# ESP32-H21 register map
Vendor: ESPRESSIF SYSTEMS (SHANGHAI) CO., LTD.; Series: ESP32 H-Series; File version: 1
CPU: RV32IMAC r0p0, little endian, no MPU, no FPU, 0 interrupt priority bits
Address unit: 32 bits
Registers are 32-bit, read-write, reset 0x0 unless marked. A register's access mark holds for its fields unless they carry their own. Offsets are from the block's base; [hi:lo] are bit positions; {n}, {i} and the like mark numbered series.

## SPI0 (part 2 of 2) — SPI (Serial Peripheral Interface) Controller 0
Base 0x60002000
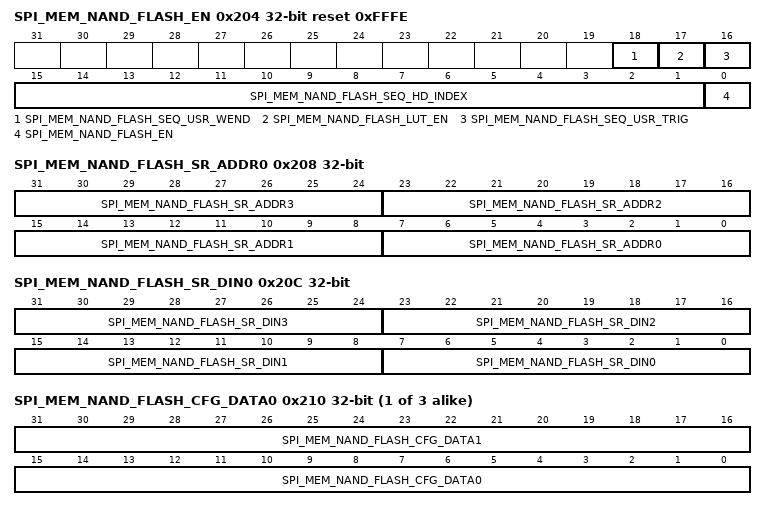
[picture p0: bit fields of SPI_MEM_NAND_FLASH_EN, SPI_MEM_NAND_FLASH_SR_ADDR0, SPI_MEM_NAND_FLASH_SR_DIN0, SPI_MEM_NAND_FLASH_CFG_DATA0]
0x204 SPI_MEM_NAND_FLASH_EN ro reset 0xFFFE — NAND FLASH control register
  [18] SPI_MEM_NAND_FLASH_SEQ_USR_WEND — Used with SPI_MEM_NAND_FLASH_SEQ_USR_TRIG to indecate the last page program ,and to excute page excute. 1: write end 0: write in a page size.
  [17] SPI_MEM_NAND_FLASH_LUT_EN — NAND FLASH spi seq & cmd lut cfg en. 1: enable 0: disable.
  [16] SPI_MEM_NAND_FLASH_SEQ_USR_TRIG — NAND FLASH spi seq user trigger configure register. SPI_MEM_NAND_FLASH_SEQ_USR_TRIG is corresponds to SPI_MEM_NAND_FLASH_SEQ_HD_INDEX[14:10].1: enable 0: disable.
  [15:1] SPI_MEM_NAND_FLASH_SEQ_HD_INDEX — NAND FLASH spi seq head index configure register. Every 5 bits represent the 1st index of a SPI CMD sequence.[14:10]:usr; [9:5]:axi_rd; [4:0]:axi_wr.
  [0] SPI_MEM_NAND_FLASH_EN — NAND FLASH function enable signal. 1: Enable NAND FLASH, Disable NOR FLASH. 0: Disable NAND FLASH, Enable NOR FLASH.
0x208 SPI_MEM_NAND_FLASH_SR_ADDR0 ro — NAND FLASH SPI SEQ control register
  [8n+7:8n] SPI_MEM_NAND_FLASH_SR_ADDR{n} (n=0..3) — configure state register address for SPI SEQ need. If OIP is in address C0H , user could configure C0H into this register
0x20C SPI_MEM_NAND_FLASH_SR_DIN0 ro — NAND FLASH SPI SEQ control register
  [8n+7:8n] SPI_MEM_NAND_FLASH_SR_DIN{n} (n=0..3) — spi read state register data to this register for SPI SEQ need. SPI_MEM_NAND_FLASH_SR_DIN0_REG corresponds to SPI_MEM_NAND_FLASH_SR_ADDR0_REG.
{0x210+4i} SPI_MEM_NAND_FLASH_CFG_DATA{i} ro (i=0..2) — NAND FLASH SPI SEQ control register
  [31:16] SPI_MEM_NAND_FLASH_CFG_DATA{2i+1} — configure data for SPI SEQ din/dout need. The data could be use to configure NAND FLASH or compare read data
  [15:0] SPI_MEM_NAND_FLASH_CFG_DATA{2i} — configure data for SPI SEQ din/dout need. The data could be use to configure NAND FLASH or compare read data
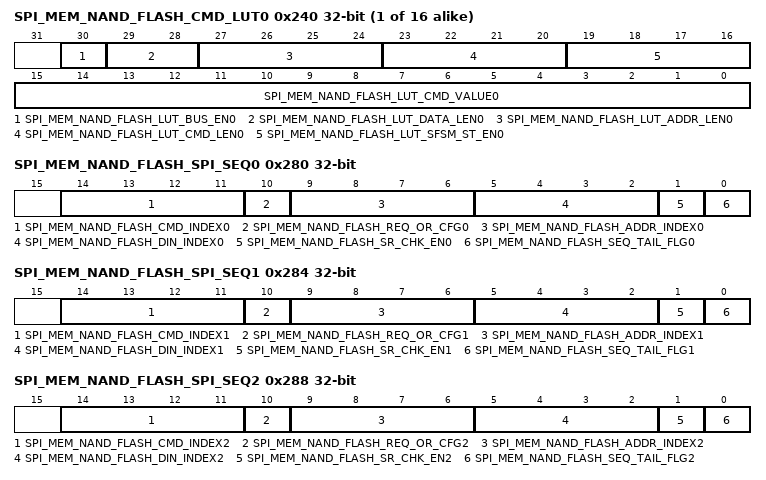
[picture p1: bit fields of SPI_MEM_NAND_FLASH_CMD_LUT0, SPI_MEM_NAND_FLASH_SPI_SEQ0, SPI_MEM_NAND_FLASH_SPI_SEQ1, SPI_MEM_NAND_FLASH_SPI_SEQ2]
{0x240+4i} SPI_MEM_NAND_FLASH_CMD_LUT{i} ro (i=0..15) — MSPI NAND FLASH CMD LUT control register
  [30] SPI_MEM_NAND_FLASH_LUT_BUS_EN{i} — MSPI NAND FLASH config spi_bus_en at cmd lut address {i},SPI could use DUAL/QUAD mode while enable, SPI could use SINGLE mode while disable.1:Enable. 0:Disable.(Note these registers are described to indicate the SPI_MEM_NAND_FLASH_CMD_LUT{i}_REG's field. The number of CMD LUT entries can be defined by the user, but cannot exceed 16 )
  [29:28] SPI_MEM_NAND_FLASH_LUT_DATA_LEN{i} — MSPI NAND FLASH config data length at cmd lut address {i}.
  [27:24] SPI_MEM_NAND_FLASH_LUT_ADDR_LEN{i} — MSPI NAND FLASH config address length at cmd lut address {i}.
  [23:20] SPI_MEM_NAND_FLASH_LUT_CMD_LEN{i} — MSPI NAND FLASH config cmd length at cmd lut address {i}.
  [19:16] SPI_MEM_NAND_FLASH_LUT_SFSM_ST_EN{i} — MSPI NAND FLASH config sfsm_st_en at cmd lut address {i}.[3]-ADDR period enable; [2]-DUMMY period enable; [1]-DIN period; [0]-DOUT period.
  [15:0] SPI_MEM_NAND_FLASH_LUT_CMD_VALUE{i} — MSPI NAND FLASH config cmd value at cmd lut address {i}.
0x280 SPI_MEM_NAND_FLASH_SPI_SEQ0 ro — NAND FLASH SPI SEQ control register
  [14:11] SPI_MEM_NAND_FLASH_CMD_INDEX0 — MSPI NAND FLASH config spi_cmd_index at spi seq index 0. Use to find SPI command in CMD LUT.(Note these registers are described to indicate the SPI_MEM_NAND_FLASH_SPI_SEQ_REG' fieldd The number of CMD LUT entries can be defined by the user, but cannot exceed 16 )
  [10] SPI_MEM_NAND_FLASH_REQ_OR_CFG0 — MSPI NAND FLASH config reg_or_cfg at spi seq index 0. 1: AXI/APB request 0: SPI SEQ configuration.
  [9:6] SPI_MEM_NAND_FLASH_ADDR_INDEX0 — MSPI NAND FLASH config addr_index at spi seq index 0. Use with SPI_MEM_NAND_FLASH_SR_ADDR
  [5:2] SPI_MEM_NAND_FLASH_DIN_INDEX0 — MSPI NAND FLASH config din_index at spi seq index 0. Use with SPI_MEM_NAND_FLASH_CFG_DATA
  [1] SPI_MEM_NAND_FLASH_SR_CHK_EN0 — MSPI NAND FLASH config sr_chk_en at spi seq index 0. 1: enable 0: disable.
  [0] SPI_MEM_NAND_FLASH_SEQ_TAIL_FLG0 — MSPI NAND FLASH config seq_tail_flg at spi seq index 0.1: The last index for sequence. 0: Not the last index.
0x284 SPI_MEM_NAND_FLASH_SPI_SEQ1 ro — NAND FLASH SPI SEQ control register
  [14:11] SPI_MEM_NAND_FLASH_CMD_INDEX1 — MSPI NAND FLASH config spi_cmd_index at spi seq index 1. Use to find SPI command in CMD LUT.(Note these registers are described to indicate the SPI_MEM_NAND_FLASH_SPI_SEQ_REG' fieldd The number of CMD LUT entries can be defined by the user, but cannot exceed 16 )
  [10] SPI_MEM_NAND_FLASH_REQ_OR_CFG1 — MSPI NAND FLASH config reg_or_cfg at spi seq index 1. 1: AXI/APB request 0: SPI SEQ configuration.
  [9:6] SPI_MEM_NAND_FLASH_ADDR_INDEX1 — MSPI NAND FLASH config addr_index at spi seq index 1. Use with SPI_MEM_NAND_FLASH_SR_ADDR
  [5:2] SPI_MEM_NAND_FLASH_DIN_INDEX1 — MSPI NAND FLASH config din_index at spi seq index 1. Use with SPI_MEM_NAND_FLASH_CFG_DATA
  [1] SPI_MEM_NAND_FLASH_SR_CHK_EN1 — MSPI NAND FLASH config sr_chk_en at spi seq index 1. 1: enable 0: disable.
  [0] SPI_MEM_NAND_FLASH_SEQ_TAIL_FLG1 — MSPI NAND FLASH config seq_tail_flg at spi seq index 1.1: The last index for sequence. 0: Not the last index.
0x288 SPI_MEM_NAND_FLASH_SPI_SEQ2 ro — NAND FLASH SPI SEQ control register
  [14:11] SPI_MEM_NAND_FLASH_CMD_INDEX2 — MSPI NAND FLASH config spi_cmd_index at spi seq index 2. Use to find SPI command in CMD LUT.(Note these registers are described to indicate the SPI_MEM_NAND_FLASH_SPI_SEQ_REG' fieldd The number of CMD LUT entries can be defined by the user, but cannot exceed 16 )
  [10] SPI_MEM_NAND_FLASH_REQ_OR_CFG2 — MSPI NAND FLASH config reg_or_cfg at spi seq index 2. 1: AXI/APB request 0: SPI SEQ configuration.
  [9:6] SPI_MEM_NAND_FLASH_ADDR_INDEX2 — MSPI NAND FLASH config addr_index at spi seq index 2. Use with SPI_MEM_NAND_FLASH_SR_ADDR
  [5:2] SPI_MEM_NAND_FLASH_DIN_INDEX2 — MSPI NAND FLASH config din_index at spi seq index 2. Use with SPI_MEM_NAND_FLASH_CFG_DATA
  [1] SPI_MEM_NAND_FLASH_SR_CHK_EN2 — MSPI NAND FLASH config sr_chk_en at spi seq index 2. 1: enable 0: disable.
  [0] SPI_MEM_NAND_FLASH_SEQ_TAIL_FLG2 — MSPI NAND FLASH config seq_tail_flg at spi seq index 2.1: The last index for sequence. 0: Not the last index.
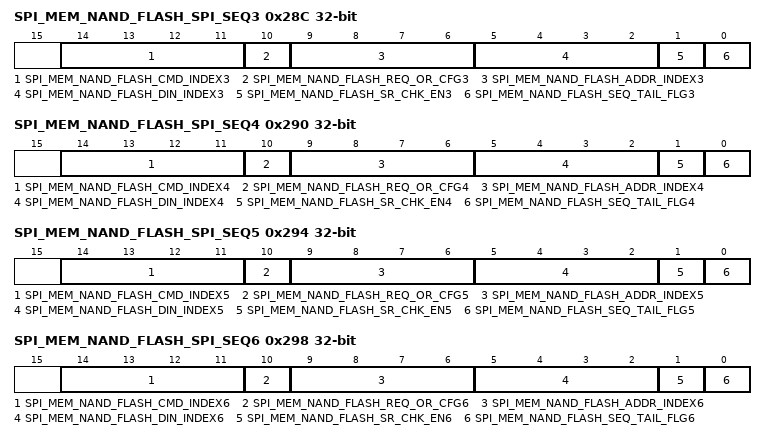
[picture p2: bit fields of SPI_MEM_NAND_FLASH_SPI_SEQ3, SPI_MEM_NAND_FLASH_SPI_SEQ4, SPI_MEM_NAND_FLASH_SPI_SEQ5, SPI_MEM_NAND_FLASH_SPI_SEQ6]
0x28C SPI_MEM_NAND_FLASH_SPI_SEQ3 ro — NAND FLASH SPI SEQ control register
  [14:11] SPI_MEM_NAND_FLASH_CMD_INDEX3 — MSPI NAND FLASH config spi_cmd_index at spi seq index 3. Use to find SPI command in CMD LUT.(Note these registers are described to indicate the SPI_MEM_NAND_FLASH_SPI_SEQ_REG' fieldd The number of CMD LUT entries can be defined by the user, but cannot exceed 16 )
  [10] SPI_MEM_NAND_FLASH_REQ_OR_CFG3 — MSPI NAND FLASH config reg_or_cfg at spi seq index 3. 1: AXI/APB request 0: SPI SEQ configuration.
  [9:6] SPI_MEM_NAND_FLASH_ADDR_INDEX3 — MSPI NAND FLASH config addr_index at spi seq index 3. Use with SPI_MEM_NAND_FLASH_SR_ADDR
  [5:2] SPI_MEM_NAND_FLASH_DIN_INDEX3 — MSPI NAND FLASH config din_index at spi seq index 3. Use with SPI_MEM_NAND_FLASH_CFG_DATA
  [1] SPI_MEM_NAND_FLASH_SR_CHK_EN3 — MSPI NAND FLASH config sr_chk_en at spi seq index 3. 1: enable 0: disable.
  [0] SPI_MEM_NAND_FLASH_SEQ_TAIL_FLG3 — MSPI NAND FLASH config seq_tail_flg at spi seq index 3.1: The last index for sequence. 0: Not the last index.
0x290 SPI_MEM_NAND_FLASH_SPI_SEQ4 ro — NAND FLASH SPI SEQ control register
  [14:11] SPI_MEM_NAND_FLASH_CMD_INDEX4 — MSPI NAND FLASH config spi_cmd_index at spi seq index 4. Use to find SPI command in CMD LUT.(Note these registers are described to indicate the SPI_MEM_NAND_FLASH_SPI_SEQ_REG' fieldd The number of CMD LUT entries can be defined by the user, but cannot exceed 16 )
  [10] SPI_MEM_NAND_FLASH_REQ_OR_CFG4 — MSPI NAND FLASH config reg_or_cfg at spi seq index 4. 1: AXI/APB request 0: SPI SEQ configuration.
  [9:6] SPI_MEM_NAND_FLASH_ADDR_INDEX4 — MSPI NAND FLASH config addr_index at spi seq index 4. Use with SPI_MEM_NAND_FLASH_SR_ADDR
  [5:2] SPI_MEM_NAND_FLASH_DIN_INDEX4 — MSPI NAND FLASH config din_index at spi seq index 4. Use with SPI_MEM_NAND_FLASH_CFG_DATA
  [1] SPI_MEM_NAND_FLASH_SR_CHK_EN4 — MSPI NAND FLASH config sr_chk_en at spi seq index 4. 1: enable 0: disable.
  [0] SPI_MEM_NAND_FLASH_SEQ_TAIL_FLG4 — MSPI NAND FLASH config seq_tail_flg at spi seq index 4.1: The last index for sequence. 0: Not the last index.
0x294 SPI_MEM_NAND_FLASH_SPI_SEQ5 ro — NAND FLASH SPI SEQ control register
  [14:11] SPI_MEM_NAND_FLASH_CMD_INDEX5 — MSPI NAND FLASH config spi_cmd_index at spi seq index 5. Use to find SPI command in CMD LUT.(Note these registers are described to indicate the SPI_MEM_NAND_FLASH_SPI_SEQ_REG' fieldd The number of CMD LUT entries can be defined by the user, but cannot exceed 16 )
  [10] SPI_MEM_NAND_FLASH_REQ_OR_CFG5 — MSPI NAND FLASH config reg_or_cfg at spi seq index 5. 1: AXI/APB request 0: SPI SEQ configuration.
  [9:6] SPI_MEM_NAND_FLASH_ADDR_INDEX5 — MSPI NAND FLASH config addr_index at spi seq index 5. Use with SPI_MEM_NAND_FLASH_SR_ADDR
  [5:2] SPI_MEM_NAND_FLASH_DIN_INDEX5 — MSPI NAND FLASH config din_index at spi seq index 5. Use with SPI_MEM_NAND_FLASH_CFG_DATA
  [1] SPI_MEM_NAND_FLASH_SR_CHK_EN5 — MSPI NAND FLASH config sr_chk_en at spi seq index 5. 1: enable 0: disable.
  [0] SPI_MEM_NAND_FLASH_SEQ_TAIL_FLG5 — MSPI NAND FLASH config seq_tail_flg at spi seq index 5.1: The last index for sequence. 0: Not the last index.
0x298 SPI_MEM_NAND_FLASH_SPI_SEQ6 ro — NAND FLASH SPI SEQ control register
  [14:11] SPI_MEM_NAND_FLASH_CMD_INDEX6 — MSPI NAND FLASH config spi_cmd_index at spi seq index 6. Use to find SPI command in CMD LUT.(Note these registers are described to indicate the SPI_MEM_NAND_FLASH_SPI_SEQ_REG' fieldd The number of CMD LUT entries can be defined by the user, but cannot exceed 16 )
  [10] SPI_MEM_NAND_FLASH_REQ_OR_CFG6 — MSPI NAND FLASH config reg_or_cfg at spi seq index 6. 1: AXI/APB request 0: SPI SEQ configuration.
  [9:6] SPI_MEM_NAND_FLASH_ADDR_INDEX6 — MSPI NAND FLASH config addr_index at spi seq index 6. Use with SPI_MEM_NAND_FLASH_SR_ADDR
  [5:2] SPI_MEM_NAND_FLASH_DIN_INDEX6 — MSPI NAND FLASH config din_index at spi seq index 6. Use with SPI_MEM_NAND_FLASH_CFG_DATA
  [1] SPI_MEM_NAND_FLASH_SR_CHK_EN6 — MSPI NAND FLASH config sr_chk_en at spi seq index 6. 1: enable 0: disable.
  [0] SPI_MEM_NAND_FLASH_SEQ_TAIL_FLG6 — MSPI NAND FLASH config seq_tail_flg at spi seq index 6.1: The last index for sequence. 0: Not the last index.
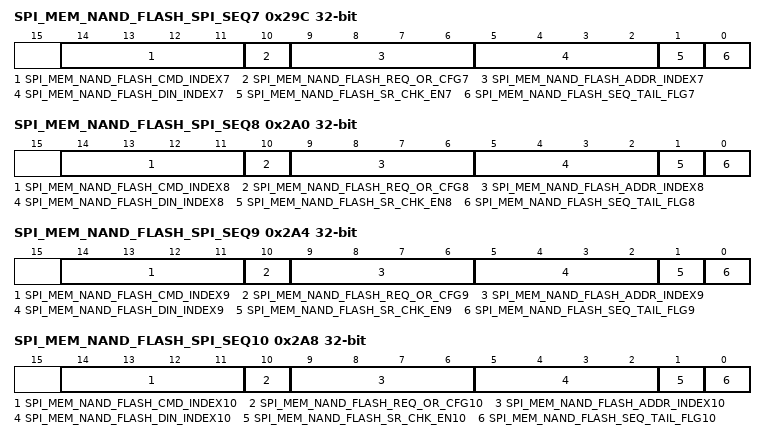
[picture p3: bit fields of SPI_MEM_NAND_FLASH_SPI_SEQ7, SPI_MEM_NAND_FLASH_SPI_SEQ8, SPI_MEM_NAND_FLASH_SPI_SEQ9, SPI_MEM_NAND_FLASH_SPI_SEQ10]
0x29C SPI_MEM_NAND_FLASH_SPI_SEQ7 ro — NAND FLASH SPI SEQ control register
  [14:11] SPI_MEM_NAND_FLASH_CMD_INDEX7 — MSPI NAND FLASH config spi_cmd_index at spi seq index 7. Use to find SPI command in CMD LUT.(Note these registers are described to indicate the SPI_MEM_NAND_FLASH_SPI_SEQ_REG' fieldd The number of CMD LUT entries can be defined by the user, but cannot exceed 16 )
  [10] SPI_MEM_NAND_FLASH_REQ_OR_CFG7 — MSPI NAND FLASH config reg_or_cfg at spi seq index 7. 1: AXI/APB request 0: SPI SEQ configuration.
  [9:6] SPI_MEM_NAND_FLASH_ADDR_INDEX7 — MSPI NAND FLASH config addr_index at spi seq index 7. Use with SPI_MEM_NAND_FLASH_SR_ADDR
  [5:2] SPI_MEM_NAND_FLASH_DIN_INDEX7 — MSPI NAND FLASH config din_index at spi seq index 7. Use with SPI_MEM_NAND_FLASH_CFG_DATA
  [1] SPI_MEM_NAND_FLASH_SR_CHK_EN7 — MSPI NAND FLASH config sr_chk_en at spi seq index 7. 1: enable 0: disable.
  [0] SPI_MEM_NAND_FLASH_SEQ_TAIL_FLG7 — MSPI NAND FLASH config seq_tail_flg at spi seq index 7.1: The last index for sequence. 0: Not the last index.
0x2A0 SPI_MEM_NAND_FLASH_SPI_SEQ8 ro — NAND FLASH SPI SEQ control register
  [14:11] SPI_MEM_NAND_FLASH_CMD_INDEX8 — MSPI NAND FLASH config spi_cmd_index at spi seq index 8. Use to find SPI command in CMD LUT.(Note these registers are described to indicate the SPI_MEM_NAND_FLASH_SPI_SEQ_REG' fieldd The number of CMD LUT entries can be defined by the user, but cannot exceed 16 )
  [10] SPI_MEM_NAND_FLASH_REQ_OR_CFG8 — MSPI NAND FLASH config reg_or_cfg at spi seq index 8. 1: AXI/APB request 0: SPI SEQ configuration.
  [9:6] SPI_MEM_NAND_FLASH_ADDR_INDEX8 — MSPI NAND FLASH config addr_index at spi seq index 8. Use with SPI_MEM_NAND_FLASH_SR_ADDR
  [5:2] SPI_MEM_NAND_FLASH_DIN_INDEX8 — MSPI NAND FLASH config din_index at spi seq index 8. Use with SPI_MEM_NAND_FLASH_CFG_DATA
  [1] SPI_MEM_NAND_FLASH_SR_CHK_EN8 — MSPI NAND FLASH config sr_chk_en at spi seq index 8. 1: enable 0: disable.
  [0] SPI_MEM_NAND_FLASH_SEQ_TAIL_FLG8 — MSPI NAND FLASH config seq_tail_flg at spi seq index 8.1: The last index for sequence. 0: Not the last index.
0x2A4 SPI_MEM_NAND_FLASH_SPI_SEQ9 ro — NAND FLASH SPI SEQ control register
  [14:11] SPI_MEM_NAND_FLASH_CMD_INDEX9 — MSPI NAND FLASH config spi_cmd_index at spi seq index 9. Use to find SPI command in CMD LUT.(Note these registers are described to indicate the SPI_MEM_NAND_FLASH_SPI_SEQ_REG' fieldd The number of CMD LUT entries can be defined by the user, but cannot exceed 16 )
  [10] SPI_MEM_NAND_FLASH_REQ_OR_CFG9 — MSPI NAND FLASH config reg_or_cfg at spi seq index 9. 1: AXI/APB request 0: SPI SEQ configuration.
  [9:6] SPI_MEM_NAND_FLASH_ADDR_INDEX9 — MSPI NAND FLASH config addr_index at spi seq index 9. Use with SPI_MEM_NAND_FLASH_SR_ADDR
  [5:2] SPI_MEM_NAND_FLASH_DIN_INDEX9 — MSPI NAND FLASH config din_index at spi seq index 9. Use with SPI_MEM_NAND_FLASH_CFG_DATA
  [1] SPI_MEM_NAND_FLASH_SR_CHK_EN9 — MSPI NAND FLASH config sr_chk_en at spi seq index 9. 1: enable 0: disable.
  [0] SPI_MEM_NAND_FLASH_SEQ_TAIL_FLG9 — MSPI NAND FLASH config seq_tail_flg at spi seq index 9.1: The last index for sequence. 0: Not the last index.
0x2A8 SPI_MEM_NAND_FLASH_SPI_SEQ10 ro — NAND FLASH SPI SEQ control register
  [14:11] SPI_MEM_NAND_FLASH_CMD_INDEX10 — MSPI NAND FLASH config spi_cmd_index at spi seq index 10. Use to find SPI command in CMD LUT.(Note these registers are described to indicate the SPI_MEM_NAND_FLASH_SPI_SEQ_REG' fieldd The number of CMD LUT entries can be defined by the user, but cannot exceed 16 )
  [10] SPI_MEM_NAND_FLASH_REQ_OR_CFG10 — MSPI NAND FLASH config reg_or_cfg at spi seq index 10. 1: AXI/APB request 0: SPI SEQ configuration.
  [9:6] SPI_MEM_NAND_FLASH_ADDR_INDEX10 — MSPI NAND FLASH config addr_index at spi seq index 10. Use with SPI_MEM_NAND_FLASH_SR_ADDR
  [5:2] SPI_MEM_NAND_FLASH_DIN_INDEX10 — MSPI NAND FLASH config din_index at spi seq index 10. Use with SPI_MEM_NAND_FLASH_CFG_DATA
  [1] SPI_MEM_NAND_FLASH_SR_CHK_EN10 — MSPI NAND FLASH config sr_chk_en at spi seq index 10. 1: enable 0: disable.
  [0] SPI_MEM_NAND_FLASH_SEQ_TAIL_FLG10 — MSPI NAND FLASH config seq_tail_flg at spi seq index 10.1: The last index for sequence. 0: Not the last index.
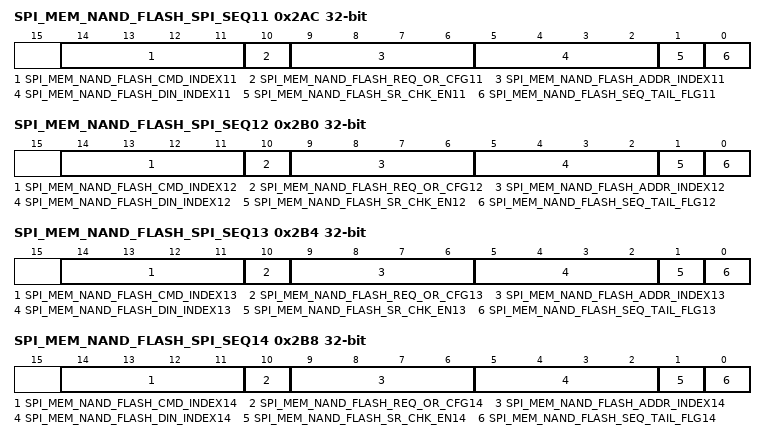
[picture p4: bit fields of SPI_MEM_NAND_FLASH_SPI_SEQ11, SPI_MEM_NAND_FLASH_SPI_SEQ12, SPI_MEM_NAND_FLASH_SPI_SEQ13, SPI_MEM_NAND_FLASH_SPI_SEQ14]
0x2AC SPI_MEM_NAND_FLASH_SPI_SEQ11 ro — NAND FLASH SPI SEQ control register
  [14:11] SPI_MEM_NAND_FLASH_CMD_INDEX11 — MSPI NAND FLASH config spi_cmd_index at spi seq index 11. Use to find SPI command in CMD LUT.(Note these registers are described to indicate the SPI_MEM_NAND_FLASH_SPI_SEQ_REG' fieldd The number of CMD LUT entries can be defined by the user, but cannot exceed 16 )
  [10] SPI_MEM_NAND_FLASH_REQ_OR_CFG11 — MSPI NAND FLASH config reg_or_cfg at spi seq index 11. 1: AXI/APB request 0: SPI SEQ configuration.
  [9:6] SPI_MEM_NAND_FLASH_ADDR_INDEX11 — MSPI NAND FLASH config addr_index at spi seq index 11. Use with SPI_MEM_NAND_FLASH_SR_ADDR
  [5:2] SPI_MEM_NAND_FLASH_DIN_INDEX11 — MSPI NAND FLASH config din_index at spi seq index 11. Use with SPI_MEM_NAND_FLASH_CFG_DATA
  [1] SPI_MEM_NAND_FLASH_SR_CHK_EN11 — MSPI NAND FLASH config sr_chk_en at spi seq index 11. 1: enable 0: disable.
  [0] SPI_MEM_NAND_FLASH_SEQ_TAIL_FLG11 — MSPI NAND FLASH config seq_tail_flg at spi seq index 11.1: The last index for sequence. 0: Not the last index.
0x2B0 SPI_MEM_NAND_FLASH_SPI_SEQ12 ro — NAND FLASH SPI SEQ control register
  [14:11] SPI_MEM_NAND_FLASH_CMD_INDEX12 — MSPI NAND FLASH config spi_cmd_index at spi seq index 12. Use to find SPI command in CMD LUT.(Note these registers are described to indicate the SPI_MEM_NAND_FLASH_SPI_SEQ_REG' fieldd The number of CMD LUT entries can be defined by the user, but cannot exceed 16 )
  [10] SPI_MEM_NAND_FLASH_REQ_OR_CFG12 — MSPI NAND FLASH config reg_or_cfg at spi seq index 12. 1: AXI/APB request 0: SPI SEQ configuration.
  [9:6] SPI_MEM_NAND_FLASH_ADDR_INDEX12 — MSPI NAND FLASH config addr_index at spi seq index 12. Use with SPI_MEM_NAND_FLASH_SR_ADDR
  [5:2] SPI_MEM_NAND_FLASH_DIN_INDEX12 — MSPI NAND FLASH config din_index at spi seq index 12. Use with SPI_MEM_NAND_FLASH_CFG_DATA
  [1] SPI_MEM_NAND_FLASH_SR_CHK_EN12 — MSPI NAND FLASH config sr_chk_en at spi seq index 12. 1: enable 0: disable.
  [0] SPI_MEM_NAND_FLASH_SEQ_TAIL_FLG12 — MSPI NAND FLASH config seq_tail_flg at spi seq index 12.1: The last index for sequence. 0: Not the last index.
0x2B4 SPI_MEM_NAND_FLASH_SPI_SEQ13 ro — NAND FLASH SPI SEQ control register
  [14:11] SPI_MEM_NAND_FLASH_CMD_INDEX13 — MSPI NAND FLASH config spi_cmd_index at spi seq index 13. Use to find SPI command in CMD LUT.(Note these registers are described to indicate the SPI_MEM_NAND_FLASH_SPI_SEQ_REG' fieldd The number of CMD LUT entries can be defined by the user, but cannot exceed 16 )
  [10] SPI_MEM_NAND_FLASH_REQ_OR_CFG13 — MSPI NAND FLASH config reg_or_cfg at spi seq index 13. 1: AXI/APB request 0: SPI SEQ configuration.
  [9:6] SPI_MEM_NAND_FLASH_ADDR_INDEX13 — MSPI NAND FLASH config addr_index at spi seq index 13. Use with SPI_MEM_NAND_FLASH_SR_ADDR
  [5:2] SPI_MEM_NAND_FLASH_DIN_INDEX13 — MSPI NAND FLASH config din_index at spi seq index 13. Use with SPI_MEM_NAND_FLASH_CFG_DATA
  [1] SPI_MEM_NAND_FLASH_SR_CHK_EN13 — MSPI NAND FLASH config sr_chk_en at spi seq index 13. 1: enable 0: disable.
  [0] SPI_MEM_NAND_FLASH_SEQ_TAIL_FLG13 — MSPI NAND FLASH config seq_tail_flg at spi seq index 13.1: The last index for sequence. 0: Not the last index.
0x2B8 SPI_MEM_NAND_FLASH_SPI_SEQ14 ro — NAND FLASH SPI SEQ control register
  [14:11] SPI_MEM_NAND_FLASH_CMD_INDEX14 — MSPI NAND FLASH config spi_cmd_index at spi seq index 14. Use to find SPI command in CMD LUT.(Note these registers are described to indicate the SPI_MEM_NAND_FLASH_SPI_SEQ_REG' fieldd The number of CMD LUT entries can be defined by the user, but cannot exceed 16 )
  [10] SPI_MEM_NAND_FLASH_REQ_OR_CFG14 — MSPI NAND FLASH config reg_or_cfg at spi seq index 14. 1: AXI/APB request 0: SPI SEQ configuration.
  [9:6] SPI_MEM_NAND_FLASH_ADDR_INDEX14 — MSPI NAND FLASH config addr_index at spi seq index 14. Use with SPI_MEM_NAND_FLASH_SR_ADDR
  [5:2] SPI_MEM_NAND_FLASH_DIN_INDEX14 — MSPI NAND FLASH config din_index at spi seq index 14. Use with SPI_MEM_NAND_FLASH_CFG_DATA
  [1] SPI_MEM_NAND_FLASH_SR_CHK_EN14 — MSPI NAND FLASH config sr_chk_en at spi seq index 14. 1: enable 0: disable.
  [0] SPI_MEM_NAND_FLASH_SEQ_TAIL_FLG14 — MSPI NAND FLASH config seq_tail_flg at spi seq index 14.1: The last index for sequence. 0: Not the last index.
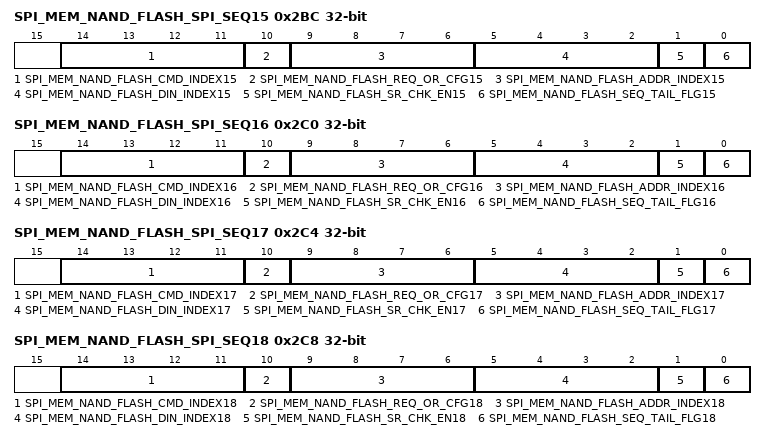
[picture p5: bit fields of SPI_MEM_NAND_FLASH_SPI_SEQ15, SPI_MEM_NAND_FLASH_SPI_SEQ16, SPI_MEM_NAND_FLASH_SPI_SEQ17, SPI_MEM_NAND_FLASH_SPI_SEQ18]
0x2BC SPI_MEM_NAND_FLASH_SPI_SEQ15 ro — NAND FLASH SPI SEQ control register
  [14:11] SPI_MEM_NAND_FLASH_CMD_INDEX15 — MSPI NAND FLASH config spi_cmd_index at spi seq index 15. Use to find SPI command in CMD LUT.(Note these registers are described to indicate the SPI_MEM_NAND_FLASH_SPI_SEQ_REG' fieldd The number of CMD LUT entries can be defined by the user, but cannot exceed 16 )
  [10] SPI_MEM_NAND_FLASH_REQ_OR_CFG15 — MSPI NAND FLASH config reg_or_cfg at spi seq index 15. 1: AXI/APB request 0: SPI SEQ configuration.
  [9:6] SPI_MEM_NAND_FLASH_ADDR_INDEX15 — MSPI NAND FLASH config addr_index at spi seq index 15. Use with SPI_MEM_NAND_FLASH_SR_ADDR
  [5:2] SPI_MEM_NAND_FLASH_DIN_INDEX15 — MSPI NAND FLASH config din_index at spi seq index 15. Use with SPI_MEM_NAND_FLASH_CFG_DATA
  [1] SPI_MEM_NAND_FLASH_SR_CHK_EN15 — MSPI NAND FLASH config sr_chk_en at spi seq index 15. 1: enable 0: disable.
  [0] SPI_MEM_NAND_FLASH_SEQ_TAIL_FLG15 — MSPI NAND FLASH config seq_tail_flg at spi seq index 15.1: The last index for sequence. 0: Not the last index.
0x2C0 SPI_MEM_NAND_FLASH_SPI_SEQ16 ro — NAND FLASH SPI SEQ control register
  [14:11] SPI_MEM_NAND_FLASH_CMD_INDEX16 — MSPI NAND FLASH config spi_cmd_index at spi seq index 16. Use to find SPI command in CMD LUT.(Note these registers are described to indicate the SPI_MEM_NAND_FLASH_SPI_SEQ_REG' fieldd The number of CMD LUT entries can be defined by the user, but cannot exceed 16 )
  [10] SPI_MEM_NAND_FLASH_REQ_OR_CFG16 — MSPI NAND FLASH config reg_or_cfg at spi seq index 16. 1: AXI/APB request 0: SPI SEQ configuration.
  [9:6] SPI_MEM_NAND_FLASH_ADDR_INDEX16 — MSPI NAND FLASH config addr_index at spi seq index 16. Use with SPI_MEM_NAND_FLASH_SR_ADDR
  [5:2] SPI_MEM_NAND_FLASH_DIN_INDEX16 — MSPI NAND FLASH config din_index at spi seq index 16. Use with SPI_MEM_NAND_FLASH_CFG_DATA
  [1] SPI_MEM_NAND_FLASH_SR_CHK_EN16 — MSPI NAND FLASH config sr_chk_en at spi seq index 16. 1: enable 0: disable.
  [0] SPI_MEM_NAND_FLASH_SEQ_TAIL_FLG16 — MSPI NAND FLASH config seq_tail_flg at spi seq index 16.1: The last index for sequence. 0: Not the last index.
0x2C4 SPI_MEM_NAND_FLASH_SPI_SEQ17 ro — NAND FLASH SPI SEQ control register
  [14:11] SPI_MEM_NAND_FLASH_CMD_INDEX17 — MSPI NAND FLASH config spi_cmd_index at spi seq index 17. Use to find SPI command in CMD LUT.(Note these registers are described to indicate the SPI_MEM_NAND_FLASH_SPI_SEQ_REG' fieldd The number of CMD LUT entries can be defined by the user, but cannot exceed 16 )
  [10] SPI_MEM_NAND_FLASH_REQ_OR_CFG17 — MSPI NAND FLASH config reg_or_cfg at spi seq index 17. 1: AXI/APB request 0: SPI SEQ configuration.
  [9:6] SPI_MEM_NAND_FLASH_ADDR_INDEX17 — MSPI NAND FLASH config addr_index at spi seq index 17. Use with SPI_MEM_NAND_FLASH_SR_ADDR
  [5:2] SPI_MEM_NAND_FLASH_DIN_INDEX17 — MSPI NAND FLASH config din_index at spi seq index 17. Use with SPI_MEM_NAND_FLASH_CFG_DATA
  [1] SPI_MEM_NAND_FLASH_SR_CHK_EN17 — MSPI NAND FLASH config sr_chk_en at spi seq index 17. 1: enable 0: disable.
  [0] SPI_MEM_NAND_FLASH_SEQ_TAIL_FLG17 — MSPI NAND FLASH config seq_tail_flg at spi seq index 17.1: The last index for sequence. 0: Not the last index.
0x2C8 SPI_MEM_NAND_FLASH_SPI_SEQ18 ro — NAND FLASH SPI SEQ control register
  [14:11] SPI_MEM_NAND_FLASH_CMD_INDEX18 — MSPI NAND FLASH config spi_cmd_index at spi seq index 18. Use to find SPI command in CMD LUT.(Note these registers are described to indicate the SPI_MEM_NAND_FLASH_SPI_SEQ_REG' fieldd The number of CMD LUT entries can be defined by the user, but cannot exceed 16 )
  [10] SPI_MEM_NAND_FLASH_REQ_OR_CFG18 — MSPI NAND FLASH config reg_or_cfg at spi seq index 18. 1: AXI/APB request 0: SPI SEQ configuration.
  [9:6] SPI_MEM_NAND_FLASH_ADDR_INDEX18 — MSPI NAND FLASH config addr_index at spi seq index 18. Use with SPI_MEM_NAND_FLASH_SR_ADDR
  [5:2] SPI_MEM_NAND_FLASH_DIN_INDEX18 — MSPI NAND FLASH config din_index at spi seq index 18. Use with SPI_MEM_NAND_FLASH_CFG_DATA
  [1] SPI_MEM_NAND_FLASH_SR_CHK_EN18 — MSPI NAND FLASH config sr_chk_en at spi seq index 18. 1: enable 0: disable.
  [0] SPI_MEM_NAND_FLASH_SEQ_TAIL_FLG18 — MSPI NAND FLASH config seq_tail_flg at spi seq index 18.1: The last index for sequence. 0: Not the last index.
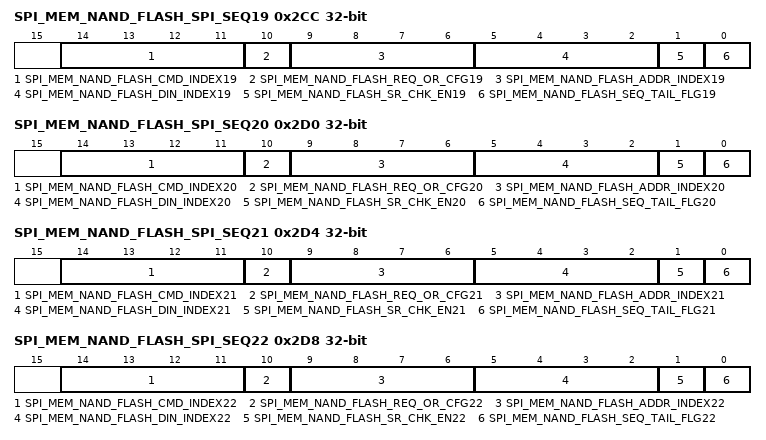
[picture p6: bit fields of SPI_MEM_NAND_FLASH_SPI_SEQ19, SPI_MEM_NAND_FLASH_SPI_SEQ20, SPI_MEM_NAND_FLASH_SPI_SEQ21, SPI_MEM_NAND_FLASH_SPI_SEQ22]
0x2CC SPI_MEM_NAND_FLASH_SPI_SEQ19 ro — NAND FLASH SPI SEQ control register
  [14:11] SPI_MEM_NAND_FLASH_CMD_INDEX19 — MSPI NAND FLASH config spi_cmd_index at spi seq index 19. Use to find SPI command in CMD LUT.(Note these registers are described to indicate the SPI_MEM_NAND_FLASH_SPI_SEQ_REG' fieldd The number of CMD LUT entries can be defined by the user, but cannot exceed 16 )
  [10] SPI_MEM_NAND_FLASH_REQ_OR_CFG19 — MSPI NAND FLASH config reg_or_cfg at spi seq index 19. 1: AXI/APB request 0: SPI SEQ configuration.
  [9:6] SPI_MEM_NAND_FLASH_ADDR_INDEX19 — MSPI NAND FLASH config addr_index at spi seq index 19. Use with SPI_MEM_NAND_FLASH_SR_ADDR
  [5:2] SPI_MEM_NAND_FLASH_DIN_INDEX19 — MSPI NAND FLASH config din_index at spi seq index 19. Use with SPI_MEM_NAND_FLASH_CFG_DATA
  [1] SPI_MEM_NAND_FLASH_SR_CHK_EN19 — MSPI NAND FLASH config sr_chk_en at spi seq index 19. 1: enable 0: disable.
  [0] SPI_MEM_NAND_FLASH_SEQ_TAIL_FLG19 — MSPI NAND FLASH config seq_tail_flg at spi seq index 19.1: The last index for sequence. 0: Not the last index.
0x2D0 SPI_MEM_NAND_FLASH_SPI_SEQ20 ro — NAND FLASH SPI SEQ control register
  [14:11] SPI_MEM_NAND_FLASH_CMD_INDEX20 — MSPI NAND FLASH config spi_cmd_index at spi seq index 20. Use to find SPI command in CMD LUT.(Note these registers are described to indicate the SPI_MEM_NAND_FLASH_SPI_SEQ_REG' fieldd The number of CMD LUT entries can be defined by the user, but cannot exceed 16 )
  [10] SPI_MEM_NAND_FLASH_REQ_OR_CFG20 — MSPI NAND FLASH config reg_or_cfg at spi seq index 20. 1: AXI/APB request 0: SPI SEQ configuration.
  [9:6] SPI_MEM_NAND_FLASH_ADDR_INDEX20 — MSPI NAND FLASH config addr_index at spi seq index 20. Use with SPI_MEM_NAND_FLASH_SR_ADDR
  [5:2] SPI_MEM_NAND_FLASH_DIN_INDEX20 — MSPI NAND FLASH config din_index at spi seq index 20. Use with SPI_MEM_NAND_FLASH_CFG_DATA
  [1] SPI_MEM_NAND_FLASH_SR_CHK_EN20 — MSPI NAND FLASH config sr_chk_en at spi seq index 20. 1: enable 0: disable.
  [0] SPI_MEM_NAND_FLASH_SEQ_TAIL_FLG20 — MSPI NAND FLASH config seq_tail_flg at spi seq index 20.1: The last index for sequence. 0: Not the last index.
0x2D4 SPI_MEM_NAND_FLASH_SPI_SEQ21 ro — NAND FLASH SPI SEQ control register
  [14:11] SPI_MEM_NAND_FLASH_CMD_INDEX21 — MSPI NAND FLASH config spi_cmd_index at spi seq index 21. Use to find SPI command in CMD LUT.(Note these registers are described to indicate the SPI_MEM_NAND_FLASH_SPI_SEQ_REG' fieldd The number of CMD LUT entries can be defined by the user, but cannot exceed 16 )
  [10] SPI_MEM_NAND_FLASH_REQ_OR_CFG21 — MSPI NAND FLASH config reg_or_cfg at spi seq index 21. 1: AXI/APB request 0: SPI SEQ configuration.
  [9:6] SPI_MEM_NAND_FLASH_ADDR_INDEX21 — MSPI NAND FLASH config addr_index at spi seq index 21. Use with SPI_MEM_NAND_FLASH_SR_ADDR
  [5:2] SPI_MEM_NAND_FLASH_DIN_INDEX21 — MSPI NAND FLASH config din_index at spi seq index 21. Use with SPI_MEM_NAND_FLASH_CFG_DATA
  [1] SPI_MEM_NAND_FLASH_SR_CHK_EN21 — MSPI NAND FLASH config sr_chk_en at spi seq index 21. 1: enable 0: disable.
  [0] SPI_MEM_NAND_FLASH_SEQ_TAIL_FLG21 — MSPI NAND FLASH config seq_tail_flg at spi seq index 21.1: The last index for sequence. 0: Not the last index.
0x2D8 SPI_MEM_NAND_FLASH_SPI_SEQ22 ro — NAND FLASH SPI SEQ control register
  [14:11] SPI_MEM_NAND_FLASH_CMD_INDEX22 — MSPI NAND FLASH config spi_cmd_index at spi seq index 22. Use to find SPI command in CMD LUT.(Note these registers are described to indicate the SPI_MEM_NAND_FLASH_SPI_SEQ_REG' fieldd The number of CMD LUT entries can be defined by the user, but cannot exceed 16 )
  [10] SPI_MEM_NAND_FLASH_REQ_OR_CFG22 — MSPI NAND FLASH config reg_or_cfg at spi seq index 22. 1: AXI/APB request 0: SPI SEQ configuration.
  [9:6] SPI_MEM_NAND_FLASH_ADDR_INDEX22 — MSPI NAND FLASH config addr_index at spi seq index 22. Use with SPI_MEM_NAND_FLASH_SR_ADDR
  [5:2] SPI_MEM_NAND_FLASH_DIN_INDEX22 — MSPI NAND FLASH config din_index at spi seq index 22. Use with SPI_MEM_NAND_FLASH_CFG_DATA
  [1] SPI_MEM_NAND_FLASH_SR_CHK_EN22 — MSPI NAND FLASH config sr_chk_en at spi seq index 22. 1: enable 0: disable.
  [0] SPI_MEM_NAND_FLASH_SEQ_TAIL_FLG22 — MSPI NAND FLASH config seq_tail_flg at spi seq index 22.1: The last index for sequence. 0: Not the last index.
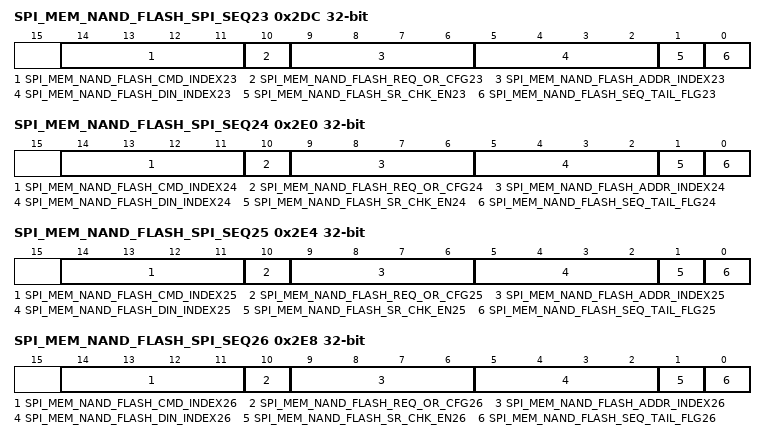
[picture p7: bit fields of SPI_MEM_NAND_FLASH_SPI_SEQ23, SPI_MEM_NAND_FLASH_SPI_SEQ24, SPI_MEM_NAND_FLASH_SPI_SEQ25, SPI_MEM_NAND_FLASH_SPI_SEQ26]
0x2DC SPI_MEM_NAND_FLASH_SPI_SEQ23 ro — NAND FLASH SPI SEQ control register
  [14:11] SPI_MEM_NAND_FLASH_CMD_INDEX23 — MSPI NAND FLASH config spi_cmd_index at spi seq index 23. Use to find SPI command in CMD LUT.(Note these registers are described to indicate the SPI_MEM_NAND_FLASH_SPI_SEQ_REG' fieldd The number of CMD LUT entries can be defined by the user, but cannot exceed 16 )
  [10] SPI_MEM_NAND_FLASH_REQ_OR_CFG23 — MSPI NAND FLASH config reg_or_cfg at spi seq index 23. 1: AXI/APB request 0: SPI SEQ configuration.
  [9:6] SPI_MEM_NAND_FLASH_ADDR_INDEX23 — MSPI NAND FLASH config addr_index at spi seq index 23. Use with SPI_MEM_NAND_FLASH_SR_ADDR
  [5:2] SPI_MEM_NAND_FLASH_DIN_INDEX23 — MSPI NAND FLASH config din_index at spi seq index 23. Use with SPI_MEM_NAND_FLASH_CFG_DATA
  [1] SPI_MEM_NAND_FLASH_SR_CHK_EN23 — MSPI NAND FLASH config sr_chk_en at spi seq index 23. 1: enable 0: disable.
  [0] SPI_MEM_NAND_FLASH_SEQ_TAIL_FLG23 — MSPI NAND FLASH config seq_tail_flg at spi seq index 23.1: The last index for sequence. 0: Not the last index.
0x2E0 SPI_MEM_NAND_FLASH_SPI_SEQ24 ro — NAND FLASH SPI SEQ control register
  [14:11] SPI_MEM_NAND_FLASH_CMD_INDEX24 — MSPI NAND FLASH config spi_cmd_index at spi seq index 24. Use to find SPI command in CMD LUT.(Note these registers are described to indicate the SPI_MEM_NAND_FLASH_SPI_SEQ_REG' fieldd The number of CMD LUT entries can be defined by the user, but cannot exceed 16 )
  [10] SPI_MEM_NAND_FLASH_REQ_OR_CFG24 — MSPI NAND FLASH config reg_or_cfg at spi seq index 24. 1: AXI/APB request 0: SPI SEQ configuration.
  [9:6] SPI_MEM_NAND_FLASH_ADDR_INDEX24 — MSPI NAND FLASH config addr_index at spi seq index 24. Use with SPI_MEM_NAND_FLASH_SR_ADDR
  [5:2] SPI_MEM_NAND_FLASH_DIN_INDEX24 — MSPI NAND FLASH config din_index at spi seq index 24. Use with SPI_MEM_NAND_FLASH_CFG_DATA
  [1] SPI_MEM_NAND_FLASH_SR_CHK_EN24 — MSPI NAND FLASH config sr_chk_en at spi seq index 24. 1: enable 0: disable.
  [0] SPI_MEM_NAND_FLASH_SEQ_TAIL_FLG24 — MSPI NAND FLASH config seq_tail_flg at spi seq index 24.1: The last index for sequence. 0: Not the last index.
0x2E4 SPI_MEM_NAND_FLASH_SPI_SEQ25 ro — NAND FLASH SPI SEQ control register
  [14:11] SPI_MEM_NAND_FLASH_CMD_INDEX25 — MSPI NAND FLASH config spi_cmd_index at spi seq index 25. Use to find SPI command in CMD LUT.(Note these registers are described to indicate the SPI_MEM_NAND_FLASH_SPI_SEQ_REG' fieldd The number of CMD LUT entries can be defined by the user, but cannot exceed 16 )
  [10] SPI_MEM_NAND_FLASH_REQ_OR_CFG25 — MSPI NAND FLASH config reg_or_cfg at spi seq index 25. 1: AXI/APB request 0: SPI SEQ configuration.
  [9:6] SPI_MEM_NAND_FLASH_ADDR_INDEX25 — MSPI NAND FLASH config addr_index at spi seq index 25. Use with SPI_MEM_NAND_FLASH_SR_ADDR
  [5:2] SPI_MEM_NAND_FLASH_DIN_INDEX25 — MSPI NAND FLASH config din_index at spi seq index 25. Use with SPI_MEM_NAND_FLASH_CFG_DATA
  [1] SPI_MEM_NAND_FLASH_SR_CHK_EN25 — MSPI NAND FLASH config sr_chk_en at spi seq index 25. 1: enable 0: disable.
  [0] SPI_MEM_NAND_FLASH_SEQ_TAIL_FLG25 — MSPI NAND FLASH config seq_tail_flg at spi seq index 25.1: The last index for sequence. 0: Not the last index.
0x2E8 SPI_MEM_NAND_FLASH_SPI_SEQ26 ro — NAND FLASH SPI SEQ control register
  [14:11] SPI_MEM_NAND_FLASH_CMD_INDEX26 — MSPI NAND FLASH config spi_cmd_index at spi seq index 26. Use to find SPI command in CMD LUT.(Note these registers are described to indicate the SPI_MEM_NAND_FLASH_SPI_SEQ_REG' fieldd The number of CMD LUT entries can be defined by the user, but cannot exceed 16 )
  [10] SPI_MEM_NAND_FLASH_REQ_OR_CFG26 — MSPI NAND FLASH config reg_or_cfg at spi seq index 26. 1: AXI/APB request 0: SPI SEQ configuration.
  [9:6] SPI_MEM_NAND_FLASH_ADDR_INDEX26 — MSPI NAND FLASH config addr_index at spi seq index 26. Use with SPI_MEM_NAND_FLASH_SR_ADDR
  [5:2] SPI_MEM_NAND_FLASH_DIN_INDEX26 — MSPI NAND FLASH config din_index at spi seq index 26. Use with SPI_MEM_NAND_FLASH_CFG_DATA
  [1] SPI_MEM_NAND_FLASH_SR_CHK_EN26 — MSPI NAND FLASH config sr_chk_en at spi seq index 26. 1: enable 0: disable.
  [0] SPI_MEM_NAND_FLASH_SEQ_TAIL_FLG26 — MSPI NAND FLASH config seq_tail_flg at spi seq index 26.1: The last index for sequence. 0: Not the last index.
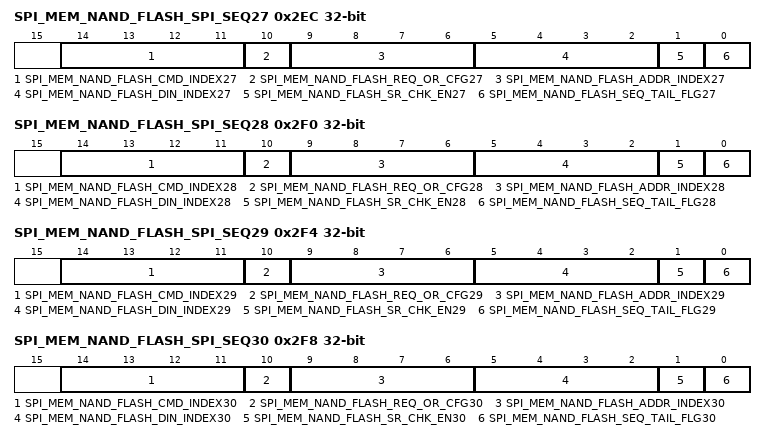
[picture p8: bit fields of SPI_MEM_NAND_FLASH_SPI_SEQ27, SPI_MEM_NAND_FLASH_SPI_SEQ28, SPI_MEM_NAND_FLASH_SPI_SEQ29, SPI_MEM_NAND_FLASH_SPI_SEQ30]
0x2EC SPI_MEM_NAND_FLASH_SPI_SEQ27 ro — NAND FLASH SPI SEQ control register
  [14:11] SPI_MEM_NAND_FLASH_CMD_INDEX27 — MSPI NAND FLASH config spi_cmd_index at spi seq index 27. Use to find SPI command in CMD LUT.(Note these registers are described to indicate the SPI_MEM_NAND_FLASH_SPI_SEQ_REG' fieldd The number of CMD LUT entries can be defined by the user, but cannot exceed 16 )
  [10] SPI_MEM_NAND_FLASH_REQ_OR_CFG27 — MSPI NAND FLASH config reg_or_cfg at spi seq index 27. 1: AXI/APB request 0: SPI SEQ configuration.
  [9:6] SPI_MEM_NAND_FLASH_ADDR_INDEX27 — MSPI NAND FLASH config addr_index at spi seq index 27. Use with SPI_MEM_NAND_FLASH_SR_ADDR
  [5:2] SPI_MEM_NAND_FLASH_DIN_INDEX27 — MSPI NAND FLASH config din_index at spi seq index 27. Use with SPI_MEM_NAND_FLASH_CFG_DATA
  [1] SPI_MEM_NAND_FLASH_SR_CHK_EN27 — MSPI NAND FLASH config sr_chk_en at spi seq index 27. 1: enable 0: disable.
  [0] SPI_MEM_NAND_FLASH_SEQ_TAIL_FLG27 — MSPI NAND FLASH config seq_tail_flg at spi seq index 27.1: The last index for sequence. 0: Not the last index.
0x2F0 SPI_MEM_NAND_FLASH_SPI_SEQ28 ro — NAND FLASH SPI SEQ control register
  [14:11] SPI_MEM_NAND_FLASH_CMD_INDEX28 — MSPI NAND FLASH config spi_cmd_index at spi seq index 28. Use to find SPI command in CMD LUT.(Note these registers are described to indicate the SPI_MEM_NAND_FLASH_SPI_SEQ_REG' fieldd The number of CMD LUT entries can be defined by the user, but cannot exceed 16 )
  [10] SPI_MEM_NAND_FLASH_REQ_OR_CFG28 — MSPI NAND FLASH config reg_or_cfg at spi seq index 28. 1: AXI/APB request 0: SPI SEQ configuration.
  [9:6] SPI_MEM_NAND_FLASH_ADDR_INDEX28 — MSPI NAND FLASH config addr_index at spi seq index 28. Use with SPI_MEM_NAND_FLASH_SR_ADDR
  [5:2] SPI_MEM_NAND_FLASH_DIN_INDEX28 — MSPI NAND FLASH config din_index at spi seq index 28. Use with SPI_MEM_NAND_FLASH_CFG_DATA
  [1] SPI_MEM_NAND_FLASH_SR_CHK_EN28 — MSPI NAND FLASH config sr_chk_en at spi seq index 28. 1: enable 0: disable.
  [0] SPI_MEM_NAND_FLASH_SEQ_TAIL_FLG28 — MSPI NAND FLASH config seq_tail_flg at spi seq index 28.1: The last index for sequence. 0: Not the last index.
0x2F4 SPI_MEM_NAND_FLASH_SPI_SEQ29 ro — NAND FLASH SPI SEQ control register
  [14:11] SPI_MEM_NAND_FLASH_CMD_INDEX29 — MSPI NAND FLASH config spi_cmd_index at spi seq index 29. Use to find SPI command in CMD LUT.(Note these registers are described to indicate the SPI_MEM_NAND_FLASH_SPI_SEQ_REG' fieldd The number of CMD LUT entries can be defined by the user, but cannot exceed 16 )
  [10] SPI_MEM_NAND_FLASH_REQ_OR_CFG29 — MSPI NAND FLASH config reg_or_cfg at spi seq index 29. 1: AXI/APB request 0: SPI SEQ configuration.
  [9:6] SPI_MEM_NAND_FLASH_ADDR_INDEX29 — MSPI NAND FLASH config addr_index at spi seq index 29. Use with SPI_MEM_NAND_FLASH_SR_ADDR
  [5:2] SPI_MEM_NAND_FLASH_DIN_INDEX29 — MSPI NAND FLASH config din_index at spi seq index 29. Use with SPI_MEM_NAND_FLASH_CFG_DATA
  [1] SPI_MEM_NAND_FLASH_SR_CHK_EN29 — MSPI NAND FLASH config sr_chk_en at spi seq index 29. 1: enable 0: disable.
  [0] SPI_MEM_NAND_FLASH_SEQ_TAIL_FLG29 — MSPI NAND FLASH config seq_tail_flg at spi seq index 29.1: The last index for sequence. 0: Not the last index.
0x2F8 SPI_MEM_NAND_FLASH_SPI_SEQ30 ro — NAND FLASH SPI SEQ control register
  [14:11] SPI_MEM_NAND_FLASH_CMD_INDEX30 — MSPI NAND FLASH config spi_cmd_index at spi seq index 30. Use to find SPI command in CMD LUT.(Note these registers are described to indicate the SPI_MEM_NAND_FLASH_SPI_SEQ_REG' fieldd The number of CMD LUT entries can be defined by the user, but cannot exceed 16 )
  [10] SPI_MEM_NAND_FLASH_REQ_OR_CFG30 — MSPI NAND FLASH config reg_or_cfg at spi seq index 30. 1: AXI/APB request 0: SPI SEQ configuration.
  [9:6] SPI_MEM_NAND_FLASH_ADDR_INDEX30 — MSPI NAND FLASH config addr_index at spi seq index 30. Use with SPI_MEM_NAND_FLASH_SR_ADDR
  [5:2] SPI_MEM_NAND_FLASH_DIN_INDEX30 — MSPI NAND FLASH config din_index at spi seq index 30. Use with SPI_MEM_NAND_FLASH_CFG_DATA
  [1] SPI_MEM_NAND_FLASH_SR_CHK_EN30 — MSPI NAND FLASH config sr_chk_en at spi seq index 30. 1: enable 0: disable.
  [0] SPI_MEM_NAND_FLASH_SEQ_TAIL_FLG30 — MSPI NAND FLASH config seq_tail_flg at spi seq index 30.1: The last index for sequence. 0: Not the last index.
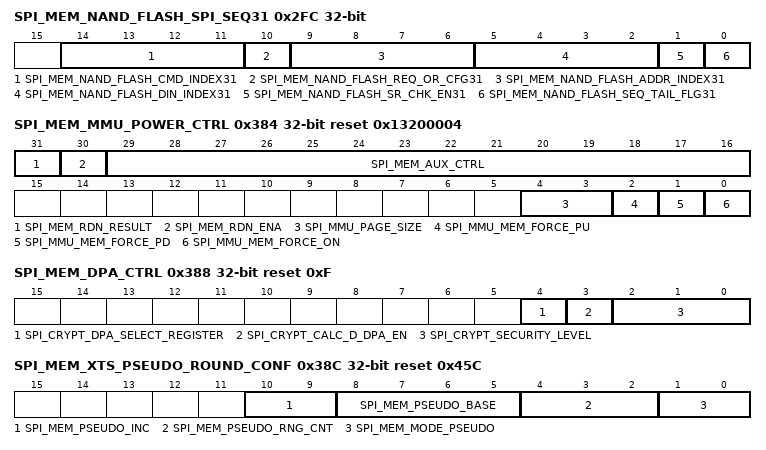
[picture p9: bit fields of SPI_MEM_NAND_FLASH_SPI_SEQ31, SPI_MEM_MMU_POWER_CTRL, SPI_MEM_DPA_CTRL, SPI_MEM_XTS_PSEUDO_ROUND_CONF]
0x2FC SPI_MEM_NAND_FLASH_SPI_SEQ31 ro — NAND FLASH SPI SEQ control register
  [14:11] SPI_MEM_NAND_FLASH_CMD_INDEX31 — MSPI NAND FLASH config spi_cmd_index at spi seq index 31. Use to find SPI command in CMD LUT.(Note these registers are described to indicate the SPI_MEM_NAND_FLASH_SPI_SEQ_REG' fieldd The number of CMD LUT entries can be defined by the user, but cannot exceed 16 )
  [10] SPI_MEM_NAND_FLASH_REQ_OR_CFG31 — MSPI NAND FLASH config reg_or_cfg at spi seq index 31. 1: AXI/APB request 0: SPI SEQ configuration.
  [9:6] SPI_MEM_NAND_FLASH_ADDR_INDEX31 — MSPI NAND FLASH config addr_index at spi seq index 31. Use with SPI_MEM_NAND_FLASH_SR_ADDR
  [5:2] SPI_MEM_NAND_FLASH_DIN_INDEX31 — MSPI NAND FLASH config din_index at spi seq index 31. Use with SPI_MEM_NAND_FLASH_CFG_DATA
  [1] SPI_MEM_NAND_FLASH_SR_CHK_EN31 — MSPI NAND FLASH config sr_chk_en at spi seq index 31. 1: enable 0: disable.
  [0] SPI_MEM_NAND_FLASH_SEQ_TAIL_FLG31 — MSPI NAND FLASH config seq_tail_flg at spi seq index 31.1: The last index for sequence. 0: Not the last index.
0x300 SPI_MEM_XTS_PLAIN_BASE — The base address of the memory that stores plaintext in Manual Encryption
  [31:0] SPI_XTS_PLAIN — This field is only used to generate include file in c case. This field is useless. Please do not use this field.
0x340 SPI_MEM_XTS_LINESIZE — Manual Encryption Line-Size register
  [1:0] SPI_XTS_LINESIZE — This bits stores the line-size parameter which will be used in manual encryption calculation. It decides how many bytes will be encrypted one time. 0: 16-bytes, 1: 32-bytes, 2: 64-bytes, 3:reserved.
0x344 SPI_MEM_XTS_DESTINATION — Manual Encryption destination register
  [0] SPI_XTS_DESTINATION — This bit stores the destination parameter which will be used in manual encryption calculation. 0: flash(default), 1: psram(reserved). Only default value can be used.
0x348 SPI_MEM_XTS_PHYSICAL_ADDRESS — Manual Encryption physical address register
  [29:0] SPI_XTS_PHYSICAL_ADDRESS — This bits stores the physical-address parameter which will be used in manual encryption calculation. This value should aligned with byte number decided by line-size parameter.
0x34C SPI_MEM_XTS_TRIGGER wo — Manual Encryption physical address register
  [0] SPI_XTS_TRIGGER — Set this bit to trigger the process of manual encryption calculation. This action should only be asserted when manual encryption status is 0. After this action, manual encryption status becomes 1. After calculation is done, manual encryption status becomes 2.
0x350 SPI_MEM_XTS_RELEASE wo — Manual Encryption physical address register
  [0] SPI_XTS_RELEASE — Set this bit to release encrypted result to mspi. This action should only be asserted when manual encryption status is 2. After this action, manual encryption status will become 3.
0x354 SPI_MEM_XTS_DESTROY wo — Manual Encryption physical address register
  [0] SPI_XTS_DESTROY — Set this bit to destroy encrypted result. This action should be asserted only when manual encryption status is 3. After this action, manual encryption status will become 0.
0x358 SPI_MEM_XTS_STATE ro — Manual Encryption physical address register
  [1:0] SPI_XTS_STATE — This bits stores the status of manual encryption. 0: idle, 1: busy of encryption calculation, 2: encryption calculation is done but the encrypted result is invisible to mspi, 3: the encrypted result is visible to mspi.
0x35C SPI_MEM_XTS_DATE reset 0x20210907 — Manual Encryption version register
  [29:0] SPI_XTS_DATE — This bits stores the last modified-time of manual encryption feature.
0x37C SPI_MEM_MMU_ITEM_CONTENT reset 0x37C — MSPI-MMU item content register
  [31:0] SPI_MMU_ITEM_CONTENT — MSPI-MMU item content
0x380 SPI_MEM_MMU_ITEM_INDEX — MSPI-MMU item index register
  [31:0] SPI_MMU_ITEM_INDEX — MSPI-MMU item index
0x384 SPI_MEM_MMU_POWER_CTRL access per field reset 0x13200004 — MSPI MMU power control register
  [31] SPI_MEM_RDN_RESULT ro — MSPI module clock domain and AXI clock domain ECO register result register
  [30] SPI_MEM_RDN_ENA rw — ECO register enable bit
  [29:16] SPI_MEM_AUX_CTRL ro — MMU PSRAM aux control register
  [4:3] SPI_MMU_PAGE_SIZE rw — 0: Max page size , 1: Max page size/2 , 2: Max page size/4, 3: Max page size/8
  [2] SPI_MMU_MEM_FORCE_PU rw — Set this bit to force mmu-memory powerup, in this case, the power should also be controlled by rtc.
  [1] SPI_MMU_MEM_FORCE_PD rw — Set this bit to force mmu-memory powerdown
  [0] SPI_MMU_MEM_FORCE_ON rw — Set this bit to enable mmu-memory clock force on
0x388 SPI_MEM_DPA_CTRL reset 0xF — SPI memory cryption DPA register
  [4] SPI_CRYPT_DPA_SELECT_REGISTER — 1: MSPI XTS DPA clock gate is controlled by SPI_CRYPT_CALC_D_DPA_EN and SPI_CRYPT_SECURITY_LEVEL. 0: Controlled by efuse bits.
  [3] SPI_CRYPT_CALC_D_DPA_EN — Only available when SPI_CRYPT_SECURITY_LEVEL is not 0. 1: Enable DPA in the calculation that using key 1 or key 2. 0: Enable DPA only in the calculation that using key 1.
  [2:0] SPI_CRYPT_SECURITY_LEVEL — Set the security level of spi mem cryption. 0: Shut off cryption DPA funtion. 1-7: The bigger the number is, the more secure the cryption is. (Note that the performance of cryption will decrease together with this number increasing)
0x38C SPI_MEM_XTS_PSEUDO_ROUND_CONF reset 0x45C — SPI memory cryption PSEUDO register
  [10:9] SPI_MEM_PSEUDO_INC — xts aes peseudo function increment round that will be peformed randomly between 0 & 2**(inc+1).
  [8:5] SPI_MEM_PSEUDO_BASE — xts aes peseudo function base round that must be peformed.
  [4:2] SPI_MEM_PSEUDO_RNG_CNT — xts aes peseudo function base round that must be peformed.
  [1:0] SPI_MEM_MODE_PSEUDO — Set the mode of pseudo. 2'b00: crypto without pseudo. 2'b01: state T with pseudo and state D without pseudo. 2'b10: state T with pseudo and state D with few pseudo. 2'b11: crypto with pseudo.
0x3F0 SPI_MEM_REGISTERRND_ECO_HIGH reset 0x37C — MSPI ECO high register
  [31:0] SPI_MEM_REGISTERRND_ECO_HIGH — ECO high register
0x3F4 SPI_MEM_REGISTERRND_ECO_LOW reset 0x37C — MSPI ECO low register
  [31:0] SPI_MEM_REGISTERRND_ECO_LOW — ECO low register
0x3FC SPI_MEM_DATE reset 0x2410150 — SPI0 version control register
  [27:0] SPI_MEM_DATE — SPI0 register version.
